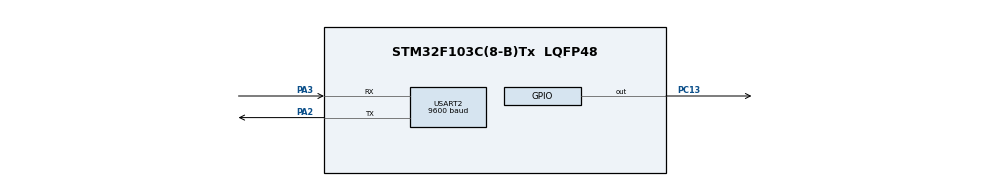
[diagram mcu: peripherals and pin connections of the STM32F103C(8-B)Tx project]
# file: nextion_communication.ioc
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Mcu.Family=STM32F1
Mcu.Name=STM32F103C(8-B)Tx
Mcu.Package=LQFP48
NVIC.PriorityGroup=NVIC_PRIORITYGROUP_4
NVIC.USART2_IRQn=true\:0\:0\:false\:false\:true\:true\:true
PA13.Mode=Serial_Wire
PA13.Signal=SYS_JTMS-SWDIO
PA14.Mode=Serial_Wire
PA14.Signal=SYS_JTCK-SWCLK
PA2.Mode=Asynchronous
PA2.Signal=USART2_TX
PA3.Mode=Asynchronous
PA3.Signal=USART2_RX
PC13-TAMPER-RTC.Signal=GPIO_Output
PD0-OSC_IN.Mode=HSE-External-Oscillator
PD0-OSC_IN.Signal=RCC_OSC_IN
PD1-OSC_OUT.Mode=HSE-External-Oscillator
PD1-OSC_OUT.Signal=RCC_OSC_OUT
ProjectManager.HeapSize=0x200
ProjectManager.StackSize=0x400
ProjectManager.TargetToolchain=STM32CubeIDE
USART2.BaudRate=9600
USART2.VirtualMode=VM_ASYNC
board=custom

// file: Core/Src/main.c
/* USER CODE BEGIN Header */
/**
  ******************************************************************************
  * @file           : main.c
  * @brief          : Main program body
  ******************************************************************************
  * @attention
  *
  * <h2><center>&copy; Copyright (c) 2020 STMicroelectronics.
  * All rights reserved.</center></h2>
  *
  * This software component is licensed by ST under BSD 3-Clause license,
  * the "License"; You may not use this file except in compliance with the
  * License. You may obtain a copy of the License at:
  *                        opensource.org/licenses/BSD-3-Clause
  *
  ******************************************************************************
  */
/* USER CODE END Header */

#include "main.h"

UART_HandleTypeDef huart2;

void SystemClock_Config(void);
static void MX_GPIO_Init(void);
static void MX_USART2_UART_Init(void);

char rx_buff[7];

int main(void)
{

  HAL_Init();
  SystemClock_Config();

  MX_GPIO_Init();
  MX_USART2_UART_Init();
__HAL_UART_ENABLE_IT(&huart2,UART_IT_RXNE);
  HAL_GPIO_WritePin(GPIOC,GPIO_PIN_13,0 );
  HAL_UART_Receive_IT(&huart2, (uint8_t *)rx_buff, 7);

  while (1)
  {
	 if(rx_buff[0] == 0x65 && rx_buff[4] == 0xFF &&
	 		  			rx_buff[5] == 0xFF && rx_buff[6] == 0xFF){
	 		  	  HAL_GPIO_TogglePin(GPIOC,GPIO_PIN_13);
	 		  	rx_buff[0]=0x00;
	 	 }
 }
}

void SystemClock_Config(void)
{
  RCC_OscInitTypeDef RCC_OscInitStruct = {0};
  RCC_ClkInitTypeDef RCC_ClkInitStruct = {0};

  /** Initializes the CPU, AHB and APB busses clocks
  */
  RCC_OscInitStruct.OscillatorType = RCC_OSCILLATORTYPE_HSI;
  RCC_OscInitStruct.HSIState = RCC_HSI_ON;
  RCC_OscInitStruct.HSICalibrationValue = RCC_HSICALIBRATION_DEFAULT;
  RCC_OscInitStruct.PLL.PLLState = RCC_PLL_NONE;
  if (HAL_RCC_OscConfig(&RCC_OscInitStruct) != HAL_OK)
  {
    Error_Handler();
  }
  /** Initializes the CPU, AHB and APB busses clocks
  */
  RCC_ClkInitStruct.ClockType = RCC_CLOCKTYPE_HCLK|RCC_CLOCKTYPE_SYSCLK
                              |RCC_CLOCKTYPE_PCLK1|RCC_CLOCKTYPE_PCLK2;
  RCC_ClkInitStruct.SYSCLKSource = RCC_SYSCLKSOURCE_HSI;
  RCC_ClkInitStruct.AHBCLKDivider = RCC_SYSCLK_DIV1;
  RCC_ClkInitStruct.APB1CLKDivider = RCC_HCLK_DIV1;
  RCC_ClkInitStruct.APB2CLKDivider = RCC_HCLK_DIV1;

  if (HAL_RCC_ClockConfig(&RCC_ClkInitStruct, FLASH_LATENCY_0) != HAL_OK)
  {
    Error_Handler();
  }
}

static void MX_USART2_UART_Init(void)
{

  huart2.Instance = USART2;
  huart2.Init.BaudRate = 9600;
  huart2.Init.WordLength = UART_WORDLENGTH_8B;
  huart2.Init.StopBits = UART_STOPBITS_1;
  huart2.Init.Parity = UART_PARITY_NONE;
  huart2.Init.Mode = UART_MODE_TX_RX;
  huart2.Init.HwFlowCtl = UART_HWCONTROL_NONE;
  huart2.Init.OverSampling = UART_OVERSAMPLING_16;
  if (HAL_UART_Init(&huart2) != HAL_OK)
  {
    Error_Handler();
  }
}

static void MX_GPIO_Init(void)
{
  GPIO_InitTypeDef GPIO_InitStruct = {0};

  /* GPIO Ports Clock Enable */
  __HAL_RCC_GPIOC_CLK_ENABLE();
  __HAL_RCC_GPIOD_CLK_ENABLE();
  __HAL_RCC_GPIOA_CLK_ENABLE();

  /*Configure GPIO pin Output Level */
  HAL_GPIO_WritePin(GPIOC, GPIO_PIN_13, GPIO_PIN_SET);

  /*Configure GPIO pin : PC13 */
  GPIO_InitStruct.Pin = GPIO_PIN_13;
  GPIO_InitStruct.Mode = GPIO_MODE_OUTPUT_PP;
  GPIO_InitStruct.Pull = GPIO_NOPULL;
  GPIO_InitStruct.Speed = GPIO_SPEED_FREQ_LOW;
  HAL_GPIO_Init(GPIOC, &GPIO_InitStruct);

}

/* USER CODE BEGIN 4 */
void HAL_UART_RxCpltCallback(UART_HandleTypeDef *huart){
	HAL_UART_Receive_IT(&huart2, (uint8_t *)rx_buff, 7);

}
void HAL_UART_TxCpltCallback(UART_HandleTypeDef *huart){

}
/* USER CODE END 4 */

 void Error_Handler(void)
{
  /* USER CODE BEGIN Error_Handler_Debug */
  /* User can add his own implementation to report the HAL error return state */
	while(1)
	  {
	    /* Error if LED2 is slowly blinking (1 sec. period) */
		HAL_GPIO_TogglePin(GPIOC,GPIO_PIN_13);
	    HAL_Delay(1000);
	  }
  /* USER CODE END Error_Handler_Debug */
}

/************************ (C) COPYRIGHT STMicroelectronics *****END OF FILE****/
